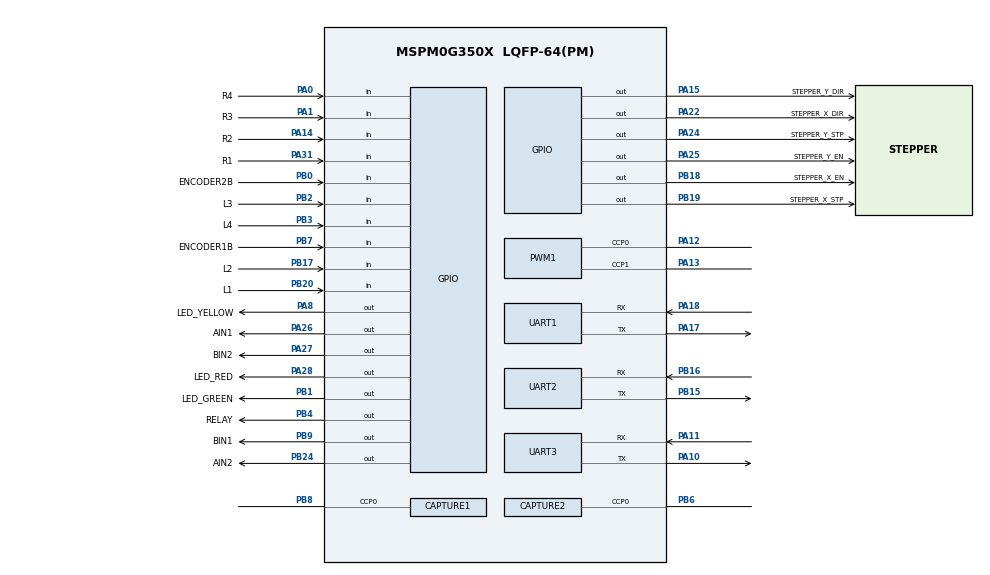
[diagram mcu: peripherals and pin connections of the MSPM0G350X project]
/**
 * @cliArgs --device "MSPM0G350X" --part "Default" --package "LQFP-64(PM)" --product "mspm0_sdk@2.01.00.03"
 * @versions {"tool":"1.21.1+3772"}
 */

/**
 * Import the modules used in this configuration.
 */
const CAPTURE  = scripting.addModule("/ti/driverlib/CAPTURE", {}, false);
const CAPTURE1 = CAPTURE.addInstance();
const CAPTURE2 = CAPTURE.addInstance();
const GPIO     = scripting.addModule("/ti/driverlib/GPIO", {}, false);
const GPIO1    = GPIO.addInstance();
const GPIO2    = GPIO.addInstance();
const GPIO3    = GPIO.addInstance();
const GPIO4    = GPIO.addInstance();
const GPIO5    = GPIO.addInstance();
const GPIO6    = GPIO.addInstance();
const PWM      = scripting.addModule("/ti/driverlib/PWM", {}, false);
const PWM1     = PWM.addInstance();
const SYSCTL   = scripting.addModule("/ti/driverlib/SYSCTL");
const TIMER    = scripting.addModule("/ti/driverlib/TIMER", {}, false);
const TIMER1   = TIMER.addInstance();
const TIMER2   = TIMER.addInstance();
const UART     = scripting.addModule("/ti/driverlib/UART", {}, false);
const UART1    = UART.addInstance();
const UART2    = UART.addInstance();
const UART3    = UART.addInstance();

/**
 * Write custom configuration values to the imported modules.
 */
const divider6       = system.clockTree["PLL_CLK2X_DIV"];
divider6.divideValue = 4;

const divider7       = system.clockTree["PLL_PDIV"];
divider7.divideValue = 2;

const divider9       = system.clockTree["UDIV"];
divider9.divideValue = 2;

const multiplier2         = system.clockTree["PLL_QDIV"];
multiplier2.multiplyValue = 10;

const mux8       = system.clockTree["HSCLKMUX"];
mux8.inputSelect = "HSCLKMUX_SYSPLL2X";

CAPTURE1.timerClkPrescale                   = 256;
CAPTURE1.timerPeriod                        = "1ms";
CAPTURE1.interrupts                         = ["CC0_DN"];
CAPTURE1.$name                              = "ENCODER1A";
CAPTURE1.peripheral.$assign                 = "TIMA0";
CAPTURE1.peripheral.ccp0Pin.$assign         = "PB8";
CAPTURE1.ccp0PinConfig.hideOutputInversion  = scripting.forceWrite(false);
CAPTURE1.ccp0PinConfig.onlyInternalResistor = scripting.forceWrite(false);
CAPTURE1.ccp0PinConfig.passedPeripheralType = scripting.forceWrite("Digital");
CAPTURE1.ccp0PinConfig.$name                = "ti_driverlib_gpio_GPIOPinGeneric8";

const Board = scripting.addModule("/ti/driverlib/Board", {}, false);

CAPTURE2.timerClkPrescale                   = 256;
CAPTURE2.timerPeriod                        = "1ms";
CAPTURE2.interrupts                         = ["CC0_DN"];
CAPTURE2.$name                              = "ENCODER2A";
CAPTURE2.peripheral.$assign                 = "TIMG6";
CAPTURE2.peripheral.ccp0Pin.$assign         = "PB6";
CAPTURE2.ccp0PinConfig.hideOutputInversion  = scripting.forceWrite(false);
CAPTURE2.ccp0PinConfig.onlyInternalResistor = scripting.forceWrite(false);
CAPTURE2.ccp0PinConfig.passedPeripheralType = scripting.forceWrite("Digital");
CAPTURE2.ccp0PinConfig.$name                = "ti_driverlib_gpio_GPIOPinGeneric9";

GPIO1.$name                         = "GPIO_GW_SENSOR";
GPIO1.associatedPins.create(8);
GPIO1.associatedPins[0].$name       = "R4";
GPIO1.associatedPins[0].direction   = "INPUT";
GPIO1.associatedPins[0].pin.$assign = "PA0";
GPIO1.associatedPins[1].$name       = "R3";
GPIO1.associatedPins[1].direction   = "INPUT";
GPIO1.associatedPins[1].pin.$assign = "PA1";
GPIO1.associatedPins[2].$name       = "R2";
GPIO1.associatedPins[2].direction   = "INPUT";
GPIO1.associatedPins[2].pin.$assign = "PA14";
GPIO1.associatedPins[3].$name       = "R1";
GPIO1.associatedPins[3].direction   = "INPUT";
GPIO1.associatedPins[3].pin.$assign = "PA31";
GPIO1.associatedPins[4].$name       = "L1";
GPIO1.associatedPins[4].direction   = "INPUT";
GPIO1.associatedPins[4].pin.$assign = "PB20";
GPIO1.associatedPins[5].$name       = "L2";
GPIO1.associatedPins[5].direction   = "INPUT";
GPIO1.associatedPins[5].pin.$assign = "PB17";
GPIO1.associatedPins[6].$name       = "L3";
GPIO1.associatedPins[6].direction   = "INPUT";
GPIO1.associatedPins[6].pin.$assign = "PB2";
GPIO1.associatedPins[7].$name       = "L4";
GPIO1.associatedPins[7].direction   = "INPUT";
GPIO1.associatedPins[7].pin.$assign = "PB3";

GPIO2.$name                         = "GPIO_MOTOR";
GPIO2.associatedPins.create(4);
GPIO2.associatedPins[0].$name       = "AIN1";
GPIO2.associatedPins[0].pin.$assign = "PA26";
GPIO2.associatedPins[1].$name       = "AIN2";
GPIO2.associatedPins[1].pin.$assign = "PB24";
GPIO2.associatedPins[2].$name       = "BIN1";
GPIO2.associatedPins[2].pin.$assign = "PB9";
GPIO2.associatedPins[3].$name       = "BIN2";
GPIO2.associatedPins[3].pin.$assign = "PA27";

GPIO3.$name                         = "GPIO_ENCODER";
GPIO3.associatedPins.create(2);
GPIO3.associatedPins[0].$name       = "ENCODER1B";
GPIO3.associatedPins[0].direction   = "INPUT";
GPIO3.associatedPins[0].pin.$assign = "PB7";
GPIO3.associatedPins[1].$name       = "ENCODER2B";
GPIO3.associatedPins[1].direction   = "INPUT";
GPIO3.associatedPins[1].pin.$assign = "PB0";

GPIO4.$name                         = "GPIO_STEPPER";
GPIO4.associatedPins.create(6);
GPIO4.associatedPins[0].$name       = "STEPPER_X_STP";
GPIO4.associatedPins[0].pin.$assign = "PB19";
GPIO4.associatedPins[1].$name       = "STEPPER_X_DIR";
GPIO4.associatedPins[1].pin.$assign = "PA22";
GPIO4.associatedPins[2].$name       = "STEPPER_X_EN";
GPIO4.associatedPins[2].pin.$assign = "PB18";
GPIO4.associatedPins[3].$name       = "STEPPER_Y_STP";
GPIO4.associatedPins[3].pin.$assign = "PA24";
GPIO4.associatedPins[4].$name       = "STEPPER_Y_DIR";
GPIO4.associatedPins[4].pin.$assign = "PA15";
GPIO4.associatedPins[5].$name       = "STEPPER_Y_EN";
GPIO4.associatedPins[5].pin.$assign = "PA25";

GPIO5.$name                          = "GPIO_LED";
GPIO5.associatedPins.create(3);
GPIO5.associatedPins[0].$name        = "LED_RED";
GPIO5.associatedPins[0].initialValue = "SET";
GPIO5.associatedPins[0].pin.$assign  = "PA28";
GPIO5.associatedPins[1].$name        = "LED_GREEN";
GPIO5.associatedPins[1].initialValue = "SET";
GPIO5.associatedPins[1].pin.$assign  = "PB1";
GPIO5.associatedPins[2].$name        = "LED_YELLOW";
GPIO5.associatedPins[2].initialValue = "SET";
GPIO5.associatedPins[2].pin.$assign  = "PA8";

GPIO6.$name                         = "GPIO_RELAY";
GPIO6.associatedPins[0].$name       = "RELAY";
GPIO6.associatedPins[0].pin.$assign = "PB4";

PWM1.$name                      = "PWM_0";
PWM1.pwmMode                    = "EDGE_ALIGN_UP";
PWM1.timerStartTimer            = true;
PWM1.peripheral.$assign         = "TIMG0";
PWM1.peripheral.ccp0Pin.$assign = "PA12";
PWM1.peripheral.ccp1Pin.$assign = "PA13";
PWM1.PWM_CHANNEL_0.$name        = "ti_driverlib_pwm_PWMTimerCC0";
PWM1.PWM_CHANNEL_1.$name        = "ti_driverlib_pwm_PWMTimerCC1";
PWM1.ccp0PinConfig.$name        = "ti_driverlib_gpio_GPIOPinGeneric10";
PWM1.ccp1PinConfig.$name        = "ti_driverlib_gpio_GPIOPinGeneric11";

SYSCTL.forceDefaultClkConfig = true;
SYSCTL.clockTreeEn           = true;

TIMER1.$name              = "TIMER_STEPPER_X";
TIMER1.timerMode          = "PERIODIC";
TIMER1.timerPeriod        = "1ms";
TIMER1.timerClkDiv        = 2;
TIMER1.interrupts         = ["ZERO"];
TIMER1.peripheral.$assign = "TIMG7";

TIMER2.$name              = "TIMER_STEPPER_Y";
TIMER2.timerPeriod        = "1 ms";
TIMER2.timerMode          = "PERIODIC";
TIMER2.timerClkDiv        = 2;
TIMER2.interrupts         = ["ZERO"];
TIMER2.interruptPriority  = "0";
TIMER2.peripheral.$assign = "TIMA1";

UART1.$name                            = "UART_HMI";
UART1.targetBaudRate                   = 115200;
UART1.enabledInterrupts                = ["RX"];
UART1.interruptPriority                = "0";
UART1.peripheral.$assign               = "UART1";
UART1.peripheral.rxPin.$assign         = "PA18";
UART1.peripheral.txPin.$assign         = "PA17";
UART1.txPinConfig.direction            = scripting.forceWrite("OUTPUT");
UART1.txPinConfig.hideOutputInversion  = scripting.forceWrite(false);
UART1.txPinConfig.onlyInternalResistor = scripting.forceWrite(false);
UART1.txPinConfig.passedPeripheralType = scripting.forceWrite("Digital");
UART1.txPinConfig.$name                = "ti_driverlib_gpio_GPIOPinGeneric2";
UART1.rxPinConfig.hideOutputInversion  = scripting.forceWrite(false);
UART1.rxPinConfig.onlyInternalResistor = scripting.forceWrite(false);
UART1.rxPinConfig.passedPeripheralType = scripting.forceWrite("Digital");
UART1.rxPinConfig.$name                = "ti_driverlib_gpio_GPIOPinGeneric3";

UART2.$name                            = "UART_RASPBERRYPI";
UART2.targetBaudRate                   = 115200;
UART2.enabledInterrupts                = ["RX"];
UART2.interruptPriority                = "1";
UART2.peripheral.$assign               = "UART2";
UART2.peripheral.rxPin.$assign         = "PB16";
UART2.peripheral.txPin.$assign         = "PB15";
UART2.txPinConfig.direction            = scripting.forceWrite("OUTPUT");
UART2.txPinConfig.hideOutputInversion  = scripting.forceWrite(false);
UART2.txPinConfig.onlyInternalResistor = scripting.forceWrite(false);
UART2.txPinConfig.passedPeripheralType = scripting.forceWrite("Digital");
UART2.txPinConfig.$name                = "ti_driverlib_gpio_GPIOPinGeneric4";
UART2.rxPinConfig.hideOutputInversion  = scripting.forceWrite(false);
UART2.rxPinConfig.onlyInternalResistor = scripting.forceWrite(false);
UART2.rxPinConfig.passedPeripheralType = scripting.forceWrite("Digital");
UART2.rxPinConfig.$name                = "ti_driverlib_gpio_GPIOPinGeneric5";

UART3.$name                            = "UART_DEBUG";
UART3.targetBaudRate                   = 115200;
UART3.rxFifoThreshold                  = "DL_UART_RX_FIFO_LEVEL_ONE_ENTRY";
UART3.enabledDMATXTriggers             = "DL_UART_DMA_INTERRUPT_TX";
UART3.enableFIFO                       = true;
UART3.txFifoThreshold                  = "DL_UART_TX_FIFO_LEVEL_ONE_ENTRY";
UART3.enabledInterrupts                = ["DMA_DONE_TX","RX"];
UART3.interruptPriority                = "1";
UART3.peripheral.$assign               = "UART0";
UART3.peripheral.rxPin.$assign         = "PA11";
UART3.peripheral.txPin.$assign         = "PA10";
UART3.txPinConfig.direction            = scripting.forceWrite("OUTPUT");
UART3.txPinConfig.hideOutputInversion  = scripting.forceWrite(false);
UART3.txPinConfig.onlyInternalResistor = scripting.forceWrite(false);
UART3.txPinConfig.passedPeripheralType = scripting.forceWrite("Digital");
UART3.txPinConfig.$name                = "ti_driverlib_gpio_GPIOPinGeneric6";
UART3.rxPinConfig.hideOutputInversion  = scripting.forceWrite(false);
UART3.rxPinConfig.onlyInternalResistor = scripting.forceWrite(false);
UART3.rxPinConfig.passedPeripheralType = scripting.forceWrite("Digital");
UART3.rxPinConfig.$name                = "ti_driverlib_gpio_GPIOPinGeneric7";
UART3.DMA_CHANNEL_TX.$name             = "DMA_CH0";
UART3.DMA_CHANNEL_TX.addressMode       = "b2f";
UART3.DMA_CHANNEL_TX.srcLength         = "BYTE";
UART3.DMA_CHANNEL_TX.dstLength         = "BYTE";

/**
 * Pinmux solution for unlocked pins/peripherals. This ensures that minor changes to the automatic solver in a future
 * version of the tool will not impact the pinmux you originally saw.  These lines can be completely deleted in order to
 * re-solve from scratch.
 */
Board.peripheral.$suggestSolution                = "DEBUGSS";
Board.peripheral.swclkPin.$suggestSolution       = "PA20";
Board.peripheral.swdioPin.$suggestSolution       = "PA19";
UART3.DMA_CHANNEL_TX.peripheral.$suggestSolution = "DMA_CH0";
